AUTOSAR XML (schema 4-0-3)
package /ComponentTypes
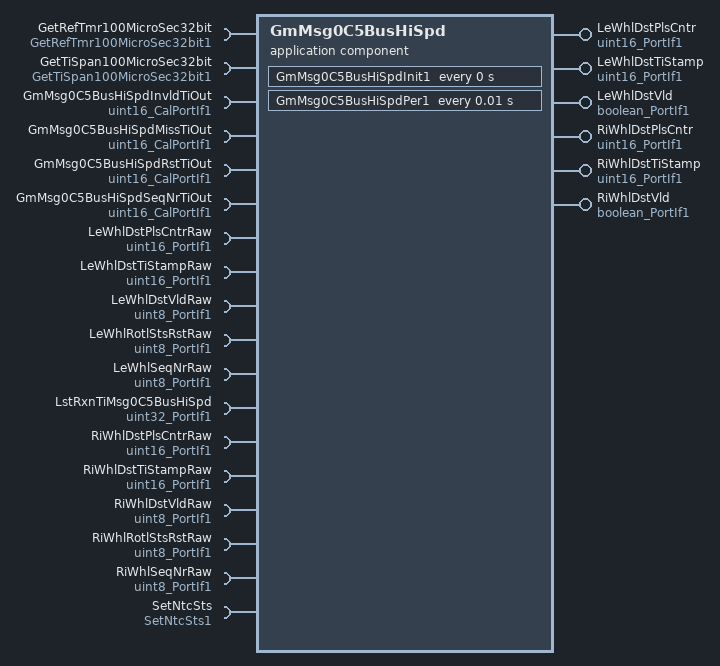
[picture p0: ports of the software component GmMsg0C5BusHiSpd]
  application sw component type GmMsg0C5BusHiSpd
    6 x provide port:
      LeWhlDstPlsCntr: nonqueued-sender-com-spec{data-element=Val, init-value=0}, provided-interface=uint16_PortIf1
      LeWhlDstTiStamp: nonqueued-sender-com-spec{data-element=Val, init-value=0}, provided-interface=uint16_PortIf1
      LeWhlDstVld: nonqueued-sender-com-spec{data-element=Logl, init-value=0}, provided-interface=boolean_PortIf1
      RiWhlDstPlsCntr: nonqueued-sender-com-spec{data-element=Val, init-value=0}, provided-interface=uint16_PortIf1
      RiWhlDstTiStamp: nonqueued-sender-com-spec{data-element=Val, init-value=0}, provided-interface=uint16_PortIf1
      RiWhlDstVld: nonqueued-sender-com-spec{data-element=Logl, init-value=0}, provided-interface=boolean_PortIf1
    18 x require port:
      GetRefTmr100MicroSec32bit: required-interface=GetRefTmr100MicroSec32bit1
      GetTiSpan100MicroSec32bit: required-interface=GetTiSpan100MicroSec32bit1
      GmMsg0C5BusHiSpdInvldTiOut: parameter-require-com-spec{init-value=1000, parameter=Val}, required-interface=uint16_CalPortIf1
      GmMsg0C5BusHiSpdMissTiOut: parameter-require-com-spec{init-value=500, parameter=Val}, required-interface=uint16_CalPortIf1
      GmMsg0C5BusHiSpdRstTiOut: parameter-require-com-spec{init-value=5, parameter=Val}, required-interface=uint16_CalPortIf1
      GmMsg0C5BusHiSpdSeqNrTiOut: parameter-require-com-spec{init-value=5, parameter=Val}, required-interface=uint16_CalPortIf1
      LeWhlDstPlsCntrRaw: nonqueued-receiver-com-spec{data-element=Val, filter=data-filter-type=ALWAYS, init-value=0}, required-interface=uint16_PortIf1
      LeWhlDstTiStampRaw: nonqueued-receiver-com-spec{data-element=Val, filter=data-filter-type=ALWAYS, init-value=0}, required-interface=uint16_PortIf1
      LeWhlDstVldRaw: nonqueued-receiver-com-spec{data-element=Val, filter=data-filter-type=ALWAYS, init-value=0}, required-interface=uint8_PortIf1
      LeWhlRotlStsRstRaw: nonqueued-receiver-com-spec{data-element=Val, filter=data-filter-type=ALWAYS, init-value=0}, required-interface=uint8_PortIf1
      LeWhlSeqNrRaw: nonqueued-receiver-com-spec{data-element=Val, filter=data-filter-type=ALWAYS, init-value=0}, required-interface=uint8_PortIf1
      LstRxnTiMsg0C5BusHiSpd: nonqueued-receiver-com-spec{data-element=Val, filter=data-filter-type=ALWAYS, init-value=0}, required-interface=uint32_PortIf1
      RiWhlDstPlsCntrRaw: nonqueued-receiver-com-spec{data-element=Val, filter=data-filter-type=ALWAYS, init-value=0}, required-interface=uint16_PortIf1
      RiWhlDstTiStampRaw: nonqueued-receiver-com-spec{data-element=Val, filter=data-filter-type=ALWAYS, init-value=0}, required-interface=uint16_PortIf1
      RiWhlDstVldRaw: nonqueued-receiver-com-spec{data-element=Val, filter=data-filter-type=ALWAYS, init-value=0}, required-interface=uint8_PortIf1
      RiWhlRotlStsRstRaw: nonqueued-receiver-com-spec{data-element=Val, filter=data-filter-type=ALWAYS, init-value=0}, required-interface=uint8_PortIf1
      RiWhlSeqNrRaw: nonqueued-receiver-com-spec{data-element=Val, filter=data-filter-type=ALWAYS, init-value=0}, required-interface=uint8_PortIf1
      SetNtcSts: required-interface=SetNtcSts1
    behavior GmMsg0C5BusHiSpd_InternalBehavior: data-type-mapping=Nexteer
      ar-typed-per-instance-memorys:
        16 x data, all with sw-calibration-access=READ-ONLY:
          GmMsg0C5BusHiSpdLeInvldTmr: type=uint32
          GmMsg0C5BusHiSpdLeRstTmr: type=uint32
          GmMsg0C5BusHiSpdLeSeqNrTmr: type=uint32
          GmMsg0C5BusHiSpdPrevLeDstPlsCnt: type=uint16
          GmMsg0C5BusHiSpdPrevLeDstTiStamp: type=uint16
          GmMsg0C5BusHiSpdPrevLeSeqNr: type=uint8
          GmMsg0C5BusHiSpdPrevLeVld: type=boolean
          GmMsg0C5BusHiSpdPrevRiDstPlsCnt: type=uint16
          GmMsg0C5BusHiSpdPrevRiDstTiStamp: type=uint16
          GmMsg0C5BusHiSpdPrevRiSeqNr: type=uint8
          GmMsg0C5BusHiSpdPrevRiVld: type=boolean
          GmMsg0C5BusHiSpdPrevRxnTi: type=uint32
          GmMsg0C5BusHiSpdRiInvldTmr: type=uint32
          GmMsg0C5BusHiSpdRiRstTmr: type=uint32
          GmMsg0C5BusHiSpdRiSeqNrTmr: type=uint32
          GmMsg0C5BusHiSpdRollgCntrRst: type=boolean
      timing event GmMsg0C5BusHiSpd_InitEvent: start-on-event=GmMsg0C5BusHiSpdInit1, period=0
      timing event TMT_GM0C9HSPer1: start-on-event=GmMsg0C5BusHiSpdPer1, period=0.01
      runnable GmMsg0C5BusHiSpdInit1
      runnable GmMsg0C5BusHiSpdPer1
        data-receive-point-by-arguments:
          11 x access:
            REC_LeWhlDstPlsCntrRaw_Val: accessed-variable=LeWhlDstPlsCntrRaw.Val
            REC_LeWhlDstTiStampRaw_Val: accessed-variable=LeWhlDstTiStampRaw.Val
            REC_LeWhlDstVldRaw_Val: accessed-variable=LeWhlDstVldRaw.Val
            REC_LeWhlRotlStsRstRaw_Val: accessed-variable=LeWhlRotlStsRstRaw.Val
            REC_LeWhlSeqNrRaw_Val: accessed-variable=LeWhlSeqNrRaw.Val
            REC_Msg0C9HSLstRxnTi_Val: accessed-variable=LstRxnTiMsg0C5BusHiSpd.Val
            REC_RiWhlDstPlsCntrRaw_Val: accessed-variable=RiWhlDstPlsCntrRaw.Val
            REC_RiWhlDstTiStampRaw_Val: accessed-variable=RiWhlDstTiStampRaw.Val
            REC_RiWhlDstVldRaw_Val: accessed-variable=RiWhlDstVldRaw.Val
            REC_RiWhlRotlStsRstRaw_Val: accessed-variable=RiWhlRotlStsRstRaw.Val
            REC_RiWhlSeqNrRaw_Val: accessed-variable=RiWhlSeqNrRaw.Val
        data-send-points:
          6 x access:
            SEND_LeWhlDstPlsCntr_Val: accessed-variable=LeWhlDstPlsCntr.Val
            SEND_LeWhlDstTiStamp_Val: accessed-variable=LeWhlDstTiStamp.Val
            SEND_LeWhlDstVld_Logl: accessed-variable=LeWhlDstVld.Logl
            SEND_RiWhlDstPlsCntr_Val: accessed-variable=RiWhlDstPlsCntr.Val
            SEND_RiWhlDstTiStamp_Val: accessed-variable=RiWhlDstTiStamp.Val
            SEND_RiWhlDstVld_Logl: accessed-variable=RiWhlDstVld.Logl
        sync call SC_GetRefTmr100MicroSec32bit_Oper: operation=GetRefTmr100MicroSec32bit.Oper, timeout=0
        sync call SC_GetTiSpan100MicroSec32bit_Oper: operation=GetTiSpan100MicroSec32bit.Oper, timeout=0
        sync call SC_SetNtcSts_Oper: operation=SetNtcSts.Oper, timeout=0
  swc implementation GmMsg0C5BusHiSpd_Implementation: behavior=GmMsg0C5BusHiSpd_InternalBehavior
    code-descriptors:
      code Default: artifact-descriptors=autosar-engineering-object={short-label=Default, category=SWSRC}
